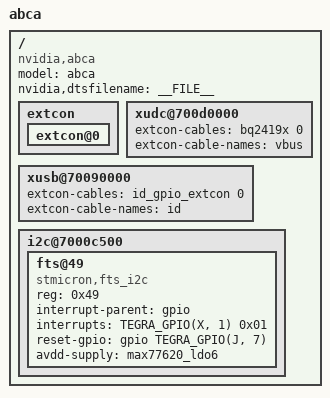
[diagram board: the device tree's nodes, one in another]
/*
 * arch/arm64/boot/dts/tegra210-abca-02-00.dts
 *
 * Copyright (c) 2014-2016, NVIDIA CORPORATION.  All rights reserved.
 *
 * This program is free software; you can redistribute it and/or modify
 * it under the terms of the GNU General Public License as published by
 * the Free Software Foundation; version 2 of the License.
 *
 * This program is distributed in the hope that it will be useful, but WITHOUT
 * ANY WARRANTY; without even the implied warranty of MERCHANTABILITY or
 * FITNESS FOR A PARTICULAR PURPOSE.  See the GNU General Public License for
 * more details.
 *
 */

#include "tegra210-abca-common.dtsi"
#include "tegra210-abca-common-disp.dtsi"
#include "abca-platforms/tegra210-abca-power-tree-02-00.dtsi"
#include <t210-common-platforms/tegra210-otg-gpio-detection-extcon.dtsi>
#include "abca-platforms/tegra210-abca-02-00-emc.dtsi"
#include "abca-platforms/tegra210-abca-sensor.dtsi"

/ {
	model = "abca";
	compatible = "nvidia,abca", "nvidia,tegra210";
	nvidia,dtsfilename = __FILE__;

	#address-cells = <2>;
	#size-cells = <2>;

	extcon {
		extcon@0 {
			status = "okay";
		};
	};

	xudc@700d0000 {
		extcon-cables = <&bq2419x 0>;
		extcon-cable-names = "vbus";
	};

	xusb@70090000 {
		extcon-cables = <&id_gpio_extcon 0>;
		extcon-cable-names = "id";
	};

	i2c@7000c500 {
		fts@49 {
			compatible = "stmicron,fts_i2c";
			reg = <0x49>;
			interrupt-parent = <&gpio>;
			interrupts = <TEGRA_GPIO(X, 1) 0x01>; /* GPIO_PX1 */
			reset-gpio = <&gpio TEGRA_GPIO(J, 7) 0>; /* GPIO_PJ7 */
			avdd-supply = <&max77620_ldo6>;
		};
	};

	/delete-node/ psy_extcon_xudc;
	/delete-node/ psy_extcon;
	/delete-node/ usb_cd@7009f000;
};
